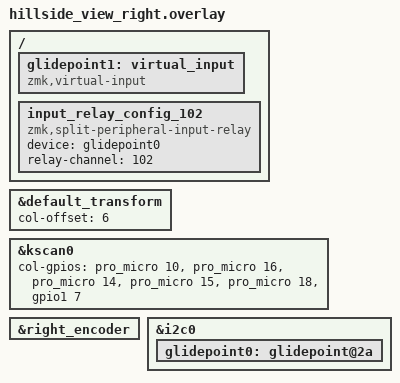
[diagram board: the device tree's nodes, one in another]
/*
 * Copyright (c) 2022 The ZMK Contributors
 *
 * SPDX-License-Identifier: MIT
 */

#include "hillside_view.dtsi"

&default_transform {
  col-offset = <6>;
};

&kscan0 {
  col-gpios
    = <&pro_micro 10 GPIO_ACTIVE_HIGH>
    , <&pro_micro 16 GPIO_ACTIVE_HIGH>
    , <&pro_micro 14 GPIO_ACTIVE_HIGH>
    , <&pro_micro 15 GPIO_ACTIVE_HIGH>
    , <&pro_micro 18 GPIO_ACTIVE_HIGH>
    , <&gpio1 7 GPIO_ACTIVE_HIGH>
    ;
};

&right_encoder {
  status = "okay";
};

// Enable I2C bus and Cirque trackpad on peripheral side
&i2c0 {
  status = "okay";
  glidepoint0: glidepoint@2a {
    status = "okay";
  };
};

/ {
  // Virtual input for keymap binding (nothing happens on peripheral side)
  glidepoint1: virtual_input {
    compatible = "zmk,virtual-input";
  };

  // Relay trackpad input from peripheral to central
  input_relay_config_102 {
    compatible = "zmk,split-peripheral-input-relay";

    // Peripheral side input device to intercept
    device = <&glidepoint0>;

    // Channel ID for event transmission (8-bit: 1-255)
    relay-channel = <102>;
  };
};
